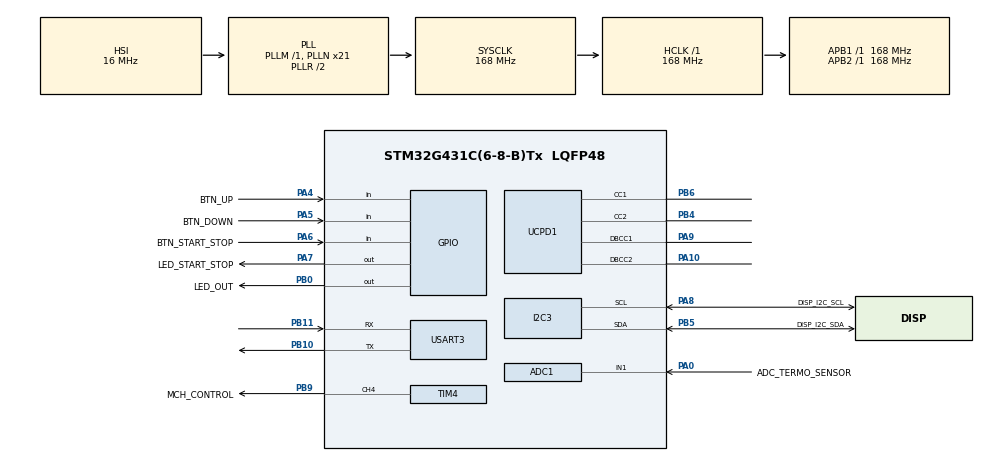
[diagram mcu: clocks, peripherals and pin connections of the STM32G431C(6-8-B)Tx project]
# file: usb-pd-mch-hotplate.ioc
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ADC1.Channel-0\#ChannelRegularConversion=ADC_CHANNEL_1
ADC1.ContinuousConvMode=ENABLE
ADC1.NbrOfConversionFlag=1
ADC1.OffsetNumber-0\#ChannelRegularConversion=ADC_OFFSET_NONE
ADC1.Overrun=ADC_OVR_DATA_OVERWRITTEN
ADC1.Rank-0\#ChannelRegularConversion=1
ADC1.SamplingTime-0\#ChannelRegularConversion=ADC_SAMPLETIME_47CYCLES_5
ADC1.master=1
I2C3.Timing=0x60505F8C
Mcu.Family=STM32G4
Mcu.Name=STM32G431C(6-8-B)Tx
Mcu.Package=LQFP48
Mcu.UserConstants=VDDA_APPLI,3300
NVIC.PriorityGroup=NVIC_PRIORITYGROUP_4
PA0.GPIO_Label=ADC_TERMO_SENSOR
PA0.Mode=IN1-Single-Ended
PA0.Signal=ADC1_IN1
PA10.Mode=EnableDeadBattery
PA10.Signal=UCPD1_DBCC2
PA13.Mode=Trace_Asynchronous_SW
PA13.Signal=SYS_JTMS-SWDIO
PA14.Mode=Trace_Asynchronous_SW
PA14.Signal=SYS_JTCK-SWCLK
PA4.GPIO_Label=BTN_UP
PA4.GPIO_PuPd=GPIO_PULLDOWN
PA4.Signal=GPIO_Input
PA5.GPIO_Label=BTN_DOWN
PA5.GPIO_PuPd=GPIO_PULLDOWN
PA5.Signal=GPIO_Input
PA6.GPIO_Label=BTN_START_STOP
PA6.GPIO_PuPd=GPIO_PULLDOWN
PA6.Signal=GPIO_Input
PA7.GPIO_Label=LED_START_STOP
PA7.Signal=GPIO_Output
PA8.GPIO_Label=DISP_I2C_SCL
PA8.GPIO_Pu=GPIO_PULLUP
PA8.GPIO_Speed=GPIO_SPEED_FREQ_VERY_HIGH
PA8.Mode=I2C
PA8.Signal=I2C3_SCL
PA9.Mode=EnableDeadBattery
PA9.Signal=UCPD1_DBCC1
PB0.GPIO_Label=LED_OUT
PB0.Signal=GPIO_Output
PB10.Mode=Asynchronous
PB10.Signal=USART3_TX
PB11.Mode=Asynchronous
PB11.Signal=USART3_RX
PB3.Mode=Trace_Asynchronous_SW
PB3.Signal=SYS_JTDO-SWO
PB4.Mode=Sink_AllSignals
PB4.Signal=UCPD1_CC2
PB5.GPIO_Label=DISP_I2C_SDA
PB5.GPIO_Pu=GPIO_PULLUP
PB5.GPIO_Speed=GPIO_SPEED_FREQ_VERY_HIGH
PB5.Mode=I2C
PB5.Signal=I2C3_SDA
PB6.Mode=Sink_AllSignals
PB6.Signal=UCPD1_CC1
PB9.GPIO_FM9=SYSCFG_FASTMODEPLUS_PB9
PB9.GPIO_Label=MCH_CONTROL
PB9.GPIO_Speed=GPIO_SPEED_FREQ_VERY_HIGH
PB9.Signal=S_TIM4_CH4
PF0-OSC_IN.Mode=HSE-External-Oscillator
PF0-OSC_IN.Signal=RCC_OSC_IN
PF1-OSC_OUT.Mode=HSE-External-Oscillator
PF1-OSC_OUT.Signal=RCC_OSC_OUT
ProjectManager.HeapSize=0x300
ProjectManager.StackSize=0x400
ProjectManager.TargetToolchain=STM32CubeIDE
RCC.ADC12Freq_Value=168000000
RCC.AHBFreq_Value=168000000
RCC.APB1Freq_Value=168000000
RCC.APB1TimFreq_Value=168000000
RCC.APB2Freq_Value=168000000
RCC.APB2TimFreq_Value=168000000
RCC.CK48CLockSelection=RCC_USBCLKSOURCE_HSI48
RCC.CortexFreq_Value=168000000
RCC.EXTERNAL_CLOCK_VALUE=12288000
RCC.HCLKFreq_Value=168000000
RCC.HSE_VALUE=16000000
RCC.HSI48_VALUE=48000000
RCC.HSI_VALUE=16000000
RCC.LSE_VALUE=32768
RCC.PLLN=21
RCC.PLLQ=RCC_PLLQ_DIV4
RCC.SYSCLKFreq_VALUE=168000000
RCC.SYSCLKSource=RCC_SYSCLKSOURCE_PLLCLK
RCC.USBFreq_Value=48000000
RCC.VCOOutputFreq_Value=336000000
SH.S_TIM4_CH4.0=TIM4_CH4,PWM Generation4 CH4
TIM4.AutoReloadPreload=TIM_AUTORELOAD_PRELOAD_ENABLE
TIM4.Channel-PWM\ Generation4\ CH4=TIM_CHANNEL_4
TIM4.PeriodNoDither=100-1
TIM4.Prescaler=168-1
USART3.VirtualMode-Asynchronous=VM_ASYNC
VP_SYS_VS_DBSignals.Mode=DisableDeadBatterySignals
VP_TIM4_VS_ClockSourceINT.Mode=Internal
board=custom

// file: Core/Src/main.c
/* USER CODE BEGIN Header */
/**
  ******************************************************************************
  * @file           : main.c
  * @brief          : Main program body
  ******************************************************************************
  * @attention
  *
  * Copyright (c) 2024 STMicroelectronics.
  * All rights reserved.
  *
  * This software is licensed under terms that can be found in the LICENSE file
  * in the root directory of this software component.
  * If no LICENSE file comes with this software, it is provided AS-IS.
  *
  ******************************************************************************
  */
/* USER CODE END Header */
#include "main.h"

/* USER CODE BEGIN Includes */
#include "../../App/app.h"
/* USER CODE END Includes */

ADC_HandleTypeDef hadc1;

I2C_HandleTypeDef hi2c3;

TIM_HandleTypeDef htim4;

UART_HandleTypeDef huart3;

void SystemClock_Config(void);
static void MX_GPIO_Init(void);
static void MX_ADC1_Init(void);
static void MX_I2C3_Init(void);
static void MX_USART3_UART_Init(void);
static void MX_TIM4_Init(void);

int main(void)
{

  /* MCU Configuration--------------------------------------------------------*/

  /* Reset of all peripherals, Initializes the Flash interface and the Systick. */
  HAL_Init();

  /* Configure the system clock */
  SystemClock_Config();

  /* Initialize all configured peripherals */
  MX_GPIO_Init();
  MX_ADC1_Init();
  MX_I2C3_Init();
  MX_USART3_UART_Init();
  MX_TIM4_Init();
  /* USER CODE BEGIN 2 */

  initApp();

  /* USER CODE END 2 */

  /* Infinite loop */
  while (1)
  {

    /* USER CODE BEGIN 3 */
    infiniteLoopIteration();
  }
  /* USER CODE END 3 */
}

void SystemClock_Config(void)
{
  RCC_OscInitTypeDef RCC_OscInitStruct = {0};
  RCC_ClkInitTypeDef RCC_ClkInitStruct = {0};

  /** Configure the main internal regulator output voltage
  */
  HAL_PWREx_ControlVoltageScaling(PWR_REGULATOR_VOLTAGE_SCALE1_BOOST);

  /** Initializes the RCC Oscillators according to the specified parameters
  * in the RCC_OscInitTypeDef structure.
  */
  RCC_OscInitStruct.OscillatorType = RCC_OSCILLATORTYPE_HSI;
  RCC_OscInitStruct.HSIState = RCC_HSI_ON;
  RCC_OscInitStruct.HSICalibrationValue = RCC_HSICALIBRATION_DEFAULT;
  RCC_OscInitStruct.PLL.PLLState = RCC_PLL_ON;
  RCC_OscInitStruct.PLL.PLLSource = RCC_PLLSOURCE_HSI;
  RCC_OscInitStruct.PLL.PLLM = RCC_PLLM_DIV1;
  RCC_OscInitStruct.PLL.PLLN = 21;
  RCC_OscInitStruct.PLL.PLLP = RCC_PLLP_DIV2;
  RCC_OscInitStruct.PLL.PLLQ = RCC_PLLQ_DIV4;
  RCC_OscInitStruct.PLL.PLLR = RCC_PLLR_DIV2;
  if (HAL_RCC_OscConfig(&RCC_OscInitStruct) != HAL_OK)
  {
    Error_Handler();
  }

  /** Initializes the CPU, AHB and APB buses clocks
  */
  RCC_ClkInitStruct.ClockType = RCC_CLOCKTYPE_HCLK|RCC_CLOCKTYPE_SYSCLK
                              |RCC_CLOCKTYPE_PCLK1|RCC_CLOCKTYPE_PCLK2;
  RCC_ClkInitStruct.SYSCLKSource = RCC_SYSCLKSOURCE_PLLCLK;
  RCC_ClkInitStruct.AHBCLKDivider = RCC_SYSCLK_DIV1;
  RCC_ClkInitStruct.APB1CLKDivider = RCC_HCLK_DIV1;
  RCC_ClkInitStruct.APB2CLKDivider = RCC_HCLK_DIV1;

  if (HAL_RCC_ClockConfig(&RCC_ClkInitStruct, FLASH_LATENCY_4) != HAL_OK)
  {
    Error_Handler();
  }
}

static void MX_ADC1_Init(void)
{

  ADC_MultiModeTypeDef multimode = {0};
  ADC_ChannelConfTypeDef sConfig = {0};

  /** Common config
  */
  hadc1.Instance = ADC1;
  hadc1.Init.ClockPrescaler = ADC_CLOCK_SYNC_PCLK_DIV4;
  hadc1.Init.Resolution = ADC_RESOLUTION_12B;
  hadc1.Init.DataAlign = ADC_DATAALIGN_RIGHT;
  hadc1.Init.GainCompensation = 0;
  hadc1.Init.ScanConvMode = ADC_SCAN_DISABLE;
  hadc1.Init.EOCSelection = ADC_EOC_SINGLE_CONV;
  hadc1.Init.LowPowerAutoWait = DISABLE;
  hadc1.Init.ContinuousConvMode = ENABLE;
  hadc1.Init.NbrOfConversion = 1;
  hadc1.Init.DiscontinuousConvMode = DISABLE;
  hadc1.Init.ExternalTrigConv = ADC_SOFTWARE_START;
  hadc1.Init.ExternalTrigConvEdge = ADC_EXTERNALTRIGCONVEDGE_NONE;
  hadc1.Init.DMAContinuousRequests = DISABLE;
  hadc1.Init.Overrun = ADC_OVR_DATA_OVERWRITTEN;
  hadc1.Init.OversamplingMode = DISABLE;
  if (HAL_ADC_Init(&hadc1) != HAL_OK)
  {
    Error_Handler();
  }

  /** Configure the ADC multi-mode
  */
  multimode.Mode = ADC_MODE_INDEPENDENT;
  if (HAL_ADCEx_MultiModeConfigChannel(&hadc1, &multimode) != HAL_OK)
  {
    Error_Handler();
  }

  /** Configure Regular Channel
  */
  sConfig.Channel = ADC_CHANNEL_1;
  sConfig.Rank = ADC_REGULAR_RANK_1;
  sConfig.SamplingTime = ADC_SAMPLETIME_47CYCLES_5;
  sConfig.SingleDiff = ADC_SINGLE_ENDED;
  sConfig.OffsetNumber = ADC_OFFSET_NONE;
  sConfig.Offset = 0;
  if (HAL_ADC_ConfigChannel(&hadc1, &sConfig) != HAL_OK)
  {
    Error_Handler();
  }
  /* USER CODE BEGIN ADC1_Init 2 */
  HAL_ADCEx_Calibration_Start(&hadc1, ADC_SINGLE_ENDED);
  HAL_ADC_Start(&hadc1);
  /* USER CODE END ADC1_Init 2 */

}

static void MX_I2C3_Init(void)
{

  hi2c3.Instance = I2C3;
  hi2c3.Init.Timing = 0x60505F8C;
  hi2c3.Init.OwnAddress1 = 0;
  hi2c3.Init.AddressingMode = I2C_ADDRESSINGMODE_7BIT;
  hi2c3.Init.DualAddressMode = I2C_DUALADDRESS_DISABLE;
  hi2c3.Init.OwnAddress2 = 0;
  hi2c3.Init.OwnAddress2Masks = I2C_OA2_NOMASK;
  hi2c3.Init.GeneralCallMode = I2C_GENERALCALL_DISABLE;
  hi2c3.Init.NoStretchMode = I2C_NOSTRETCH_DISABLE;
  if (HAL_I2C_Init(&hi2c3) != HAL_OK)
  {
    Error_Handler();
  }

  /** Configure Analogue filter
  */
  if (HAL_I2CEx_ConfigAnalogFilter(&hi2c3, I2C_ANALOGFILTER_ENABLE) != HAL_OK)
  {
    Error_Handler();
  }

  /** Configure Digital filter
  */
  if (HAL_I2CEx_ConfigDigitalFilter(&hi2c3, 0) != HAL_OK)
  {
    Error_Handler();
  }

}

static void MX_TIM4_Init(void)
{

  TIM_ClockConfigTypeDef sClockSourceConfig = {0};
  TIM_MasterConfigTypeDef sMasterConfig = {0};
  TIM_OC_InitTypeDef sConfigOC = {0};

  htim4.Instance = TIM4;
  htim4.Init.Prescaler = 168-1;
  htim4.Init.CounterMode = TIM_COUNTERMODE_UP;
  htim4.Init.Period = 99;
  htim4.Init.ClockDivision = TIM_CLOCKDIVISION_DIV1;
  htim4.Init.AutoReloadPreload = TIM_AUTORELOAD_PRELOAD_ENABLE;
  if (HAL_TIM_Base_Init(&htim4) != HAL_OK)
  {
    Error_Handler();
  }
  sClockSourceConfig.ClockSource = TIM_CLOCKSOURCE_INTERNAL;
  if (HAL_TIM_ConfigClockSource(&htim4, &sClockSourceConfig) != HAL_OK)
  {
    Error_Handler();
  }
  if (HAL_TIM_PWM_Init(&htim4) != HAL_OK)
  {
    Error_Handler();
  }
  sMasterConfig.MasterOutputTrigger = TIM_TRGO_RESET;
  sMasterConfig.MasterSlaveMode = TIM_MASTERSLAVEMODE_DISABLE;
  if (HAL_TIMEx_MasterConfigSynchronization(&htim4, &sMasterConfig) != HAL_OK)
  {
    Error_Handler();
  }
  sConfigOC.OCMode = TIM_OCMODE_PWM1;
  sConfigOC.Pulse = 0;
  sConfigOC.OCPolarity = TIM_OCPOLARITY_HIGH;
  sConfigOC.OCFastMode = TIM_OCFAST_DISABLE;
  if (HAL_TIM_PWM_ConfigChannel(&htim4, &sConfigOC, TIM_CHANNEL_4) != HAL_OK)
  {
    Error_Handler();
  }
  HAL_TIM_MspPostInit(&htim4);

}

static void MX_USART3_UART_Init(void)
{

  huart3.Instance = USART3;
  huart3.Init.BaudRate = 115200;
  huart3.Init.WordLength = UART_WORDLENGTH_8B;
  huart3.Init.StopBits = UART_STOPBITS_1;
  huart3.Init.Parity = UART_PARITY_NONE;
  huart3.Init.Mode = UART_MODE_TX_RX;
  huart3.Init.HwFlowCtl = UART_HWCONTROL_NONE;
  huart3.Init.OverSampling = UART_OVERSAMPLING_16;
  huart3.Init.OneBitSampling = UART_ONE_BIT_SAMPLE_DISABLE;
  huart3.Init.ClockPrescaler = UART_PRESCALER_DIV1;
  huart3.AdvancedInit.AdvFeatureInit = UART_ADVFEATURE_NO_INIT;
  if (HAL_UART_Init(&huart3) != HAL_OK)
  {
    Error_Handler();
  }
  if (HAL_UARTEx_SetTxFifoThreshold(&huart3, UART_TXFIFO_THRESHOLD_1_8) != HAL_OK)
  {
    Error_Handler();
  }
  if (HAL_UARTEx_SetRxFifoThreshold(&huart3, UART_RXFIFO_THRESHOLD_1_8) != HAL_OK)
  {
    Error_Handler();
  }
  if (HAL_UARTEx_DisableFifoMode(&huart3) != HAL_OK)
  {
    Error_Handler();
  }

}

static void MX_GPIO_Init(void)
{
  GPIO_InitTypeDef GPIO_InitStruct = {0};

  /* GPIO Ports Clock Enable */
  __HAL_RCC_GPIOF_CLK_ENABLE();
  __HAL_RCC_GPIOA_CLK_ENABLE();
  __HAL_RCC_GPIOB_CLK_ENABLE();

  /*Configure GPIO pin Output Level */
  HAL_GPIO_WritePin(LED_START_STOP_GPIO_Port, LED_START_STOP_Pin, GPIO_PIN_RESET);

  /*Configure GPIO pin Output Level */
  HAL_GPIO_WritePin(LED_OUT_GPIO_Port, LED_OUT_Pin, GPIO_PIN_RESET);

  /*Configure GPIO pins : BTN_UP_Pin BTN_DOWN_Pin BTN_START_STOP_Pin */
  GPIO_InitStruct.Pin = BTN_UP_Pin|BTN_DOWN_Pin|BTN_START_STOP_Pin;
  GPIO_InitStruct.Mode = GPIO_MODE_INPUT;
  GPIO_InitStruct.Pull = GPIO_PULLDOWN;
  HAL_GPIO_Init(GPIOA, &GPIO_InitStruct);

  /*Configure GPIO pin : LED_START_STOP_Pin */
  GPIO_InitStruct.Pin = LED_START_STOP_Pin;
  GPIO_InitStruct.Mode = GPIO_MODE_OUTPUT_PP;
  GPIO_InitStruct.Pull = GPIO_NOPULL;
  GPIO_InitStruct.Speed = GPIO_SPEED_FREQ_LOW;
  HAL_GPIO_Init(LED_START_STOP_GPIO_Port, &GPIO_InitStruct);

  /*Configure GPIO pin : LED_OUT_Pin */
  GPIO_InitStruct.Pin = LED_OUT_Pin;
  GPIO_InitStruct.Mode = GPIO_MODE_OUTPUT_PP;
  GPIO_InitStruct.Pull = GPIO_NOPULL;
  GPIO_InitStruct.Speed = GPIO_SPEED_FREQ_LOW;
  HAL_GPIO_Init(LED_OUT_GPIO_Port, &GPIO_InitStruct);

}

void Error_Handler(void)
{
  __disable_irq();
  while (1)
  {
  }
}
